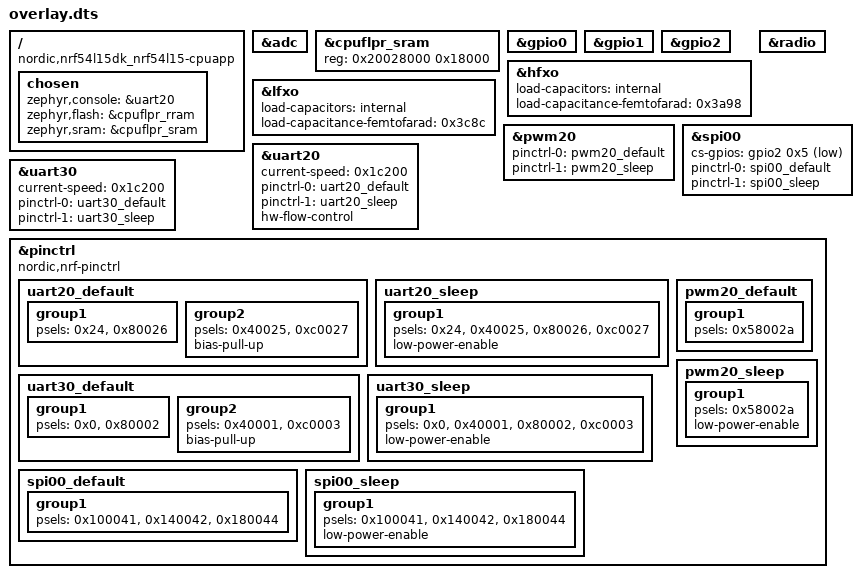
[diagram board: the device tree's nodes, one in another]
/ {
	compatible = "nordic,nrf54l15dk_nrf54l15-cpuapp";
	chosen {
		zephyr,console = &uart20;
		zephyr,flash = &cpuflpr_rram;
		zephyr,sram = &cpuflpr_sram;
	};
};
&adc{
	status = "okay";
};
&cpuflpr_sram{
	reg = < 0x20028000 0x18000 >;
	ranges = < 0x0 0x20028000 0x18000 >;
	status = "okay";
};
&gpio0{
	status = "okay";
};
&gpio1{
	status = "okay";
};
&gpio2{
	status = "okay";
};
&hfxo{
	load-capacitors = "internal";
	load-capacitance-femtofarad = < 0x3a98 >;
};
&lfxo{
	load-capacitors = "internal";
	load-capacitance-femtofarad = < 0x3c8c >;
};
&pwm20{
	status = "okay";
	pinctrl-0 = < &pwm20_default >;
	pinctrl-1 = < &pwm20_sleep >;
	pinctrl-names = "default", "sleep";
};
&radio{
	status = "okay";
};
&spi00{
	status = "okay";
	cs-gpios = < &gpio2 0x5 0x1 >;
	pinctrl-0 = < &spi00_default >;
	pinctrl-1 = < &spi00_sleep >;
	pinctrl-names = "default", "sleep";
};
&uart20{
	status = "okay";
	current-speed = < 0x1c200 >;
	pinctrl-0 = < &uart20_default >;
	pinctrl-1 = < &uart20_sleep >;
	pinctrl-names = "default", "sleep";
	hw-flow-control;
};
&uart30{
	current-speed = < 0x1c200 >;
	pinctrl-0 = < &uart30_default >;
	pinctrl-1 = < &uart30_sleep >;
	pinctrl-names = "default", "sleep";
};
&pinctrl{
	compatible = "nordic,nrf-pinctrl";
	uart20_default: uart20_default {
		group1 {
			psels = < 0x24 >, < 0x80026 >;
		};
		group2 {
			psels = < 0x40025 >, < 0xc0027 >;
			bias-pull-up;
		};
	};
	uart20_sleep: uart20_sleep {
		group1 {
			psels = < 0x24 >, < 0x40025 >, < 0x80026 >, < 0xc0027 >;
			low-power-enable;
		};
	};
	uart30_default: uart30_default {
		group1 {
			psels = < 0x0 >, < 0x80002 >;
		};
		group2 {
			psels = < 0x40001 >, < 0xc0003 >;
			bias-pull-up;
		};
	};
	uart30_sleep: uart30_sleep {
		group1 {
			psels = < 0x0 >, < 0x40001 >, < 0x80002 >, < 0xc0003 >;
			low-power-enable;
		};
	};
	spi00_default: spi00_default {
		group1 {
			psels = < 0x100041 >, < 0x140042 >, < 0x180044 >;
		};
	};
	spi00_sleep: spi00_sleep {
		group1 {
			psels = < 0x100041 >, < 0x140042 >, < 0x180044 >;
			low-power-enable;
		};
	};
	pwm20_default: pwm20_default {
		group1 {
			psels = < 0x58002a >;
		};
	};
	pwm20_sleep: pwm20_sleep {
		group1 {
			psels = < 0x58002a >;
			low-power-enable;
		};
	};
};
